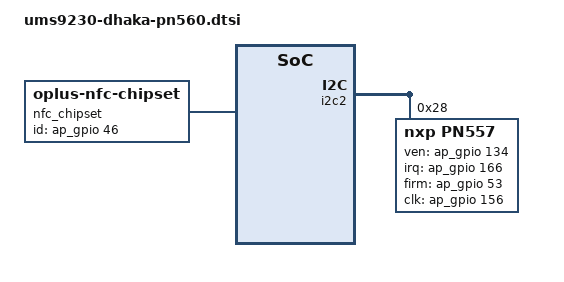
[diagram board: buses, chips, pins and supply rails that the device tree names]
/*ATL 68K*/
/ {
	nfc_chipset:nfc_chipset {
		compatible = "oplus-nfc-chipset";
		mixed-chipset = <1>;
		id-gpio = <&ap_gpio 46 0>;
		id_count = <2>;
		id-0-key = <0>;
		id-0-value-chipset = "THN31F";
		manifest = "/vendor/etc/vintf/manifest/nfc-service-tms.xml";
		id-0-value-manifest-path = "/odm/etc/vintf/manifest_thn31f.xml";
		id-0-value-feature-path = "/odm/etc/feature_thn31f.xml";
		id-1-key = <1>;
		id-1-value-chipset = "PN560";
		id-1-value-manifest-path = "/odm/etc/vintf/manifest_pn560.xml";
		id-1-value-feature-path = "/odm/etc/com.oplus.nfc_feature_pn560.xml";
	};
};

&i2c2 {
	status = "okay";
	#address-cells = <1>;
	#size-cells = <0>;
        pn557: pn557@28{
                compatible = "nxp,pn557";
                reg = <0x28>;
                clock-names = "pn557_clk","source","enable";
                clocks = <&aon_clk CLK_AUX0>, <&ext_26m>, <&aonapb_gate CLK_AUX0_EB>;
                nxp,ven-gpio = <&ap_gpio 134 0>;
                nxp,irq-gpio = <&ap_gpio 166 0>;
                nxp,firm-gpio = <&ap_gpio 53 0>;
                nxp,clk-gpio = <&ap_gpio 156 0>;
        };
};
